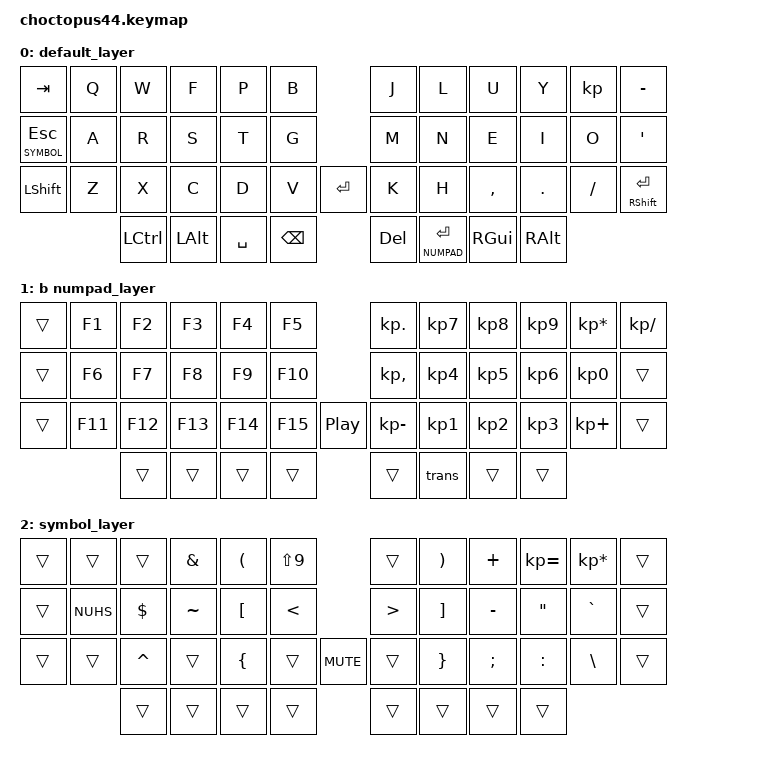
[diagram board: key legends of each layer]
/*
 * Copyright (c) 2021 The ZMK Contributors
 *
 * SPDX-License-Identifier: MIT
 */

#include <behaviors.dtsi>
#include <dt-bindings/zmk/keys.h>
#include <dt-bindings/zmk/bt.h>
#include <dt-bindings/zmk/rgb.h>

#define DEFAULT 0
#define NUMPAD  1
#define SYMBOL  2

&mt {
    tapping-term-ms = <400>;
};

/ {
  keymap {
    compatible = "zmk,keymap";

    /*
     * Colemak DH Base Layout
     */

    default_layer {
      bindings = <
        &kp TAB            &kp Q     &kp W       &kp F     &kp P     &kp B                &kp J     &kp L             &kp U      &kp Y    &kp       &kp MINUS
        &lt SYMBOL ESC     &kp A     &kp R       &kp S     &kp T     &kp G                &kp M     &kp N             &kp E      &kp I    &kp O     &kp APOS
        &kp LSHFT          &kp Z     &kp X       &kp C     &kp D     &kp V      &kp RET   &kp K     &kp H             &kp COMMA  &kp DOT  &kp FSLH  &mt RSHFT RET
                                     &kp LCTRL   &kp LALT  &kp SPACE &kp BSPC             &kp DEL   &lt NUMPAD ENTER  &kp RGUI   &kp RALT
      >;
      sensor-bindings = <&inc_dec_kp LEFT RIGHT>;
    };

    /*
     * F-Keys on the left side, Numpad on the right side
     */b

    numpad_layer {
      bindings = <
        &trans    &kp F1    &kp F2  &kp F3   &kp F4   &kp F5                          &kp KP_DOT       &kp KP_N7   &kp KP_N8    &kp KP_N9   &kp KP_MULTIPLY  &kp KP_DIVIDE
        &trans    &kp F6    &kp F7  &kp F8   &kp F9   &kp F10                         &kp KP_COMMA     &kp KP_N4   &kp KP_N5    &kp KP_N6   &kp KP_N0        &trans
        &trans    &kp F11   &kp F12 &kp F13  &kp F14  &kp F15     &kp C_PLAY_PAUSE    &kp KP_MINUS     &kp KP_N1   &kp KP_N2    &kp KP_N3   &kp KP_PLUS      &trans
                            &trans  &trans   &trans   &trans                          &trans           &kp trans   &trans       &trans
      >;
      sensor-bindings = <&inc_dec_kp C_VOL_DN C_VOL_UP>;
    };

    symbol_layer {
      bindings = <
        &trans      &trans       &trans             &kp AMPERSAND    &kp LPAR   &kp LS(N9)                   &trans        &kp RPAR   &kp PLUS    &kp KP_EQUAL  &kp KP_MULTIPLY    &trans
        &trans      &kp NUHS     &kp DOLLAR         &kp TILDE        &kp LBKT   &kp LT                       &kp GT        &kp RBKT   &kp MINUS   &kp DQT       &kp GRAVE          &trans
        &trans      &trans       &kp CARET          &trans           &kp LBRC   &trans       &kp C_MUTE      &trans        &kp RBRC   &kp SEMI    &kp COLON     &kp BSLH           &trans
                                 &trans             &trans           &trans     &trans                       &trans        &trans     &trans      &trans
      >;
      sensor-bindings = <&inc_dec_kp UP DOWN>;
    };

  };
};
